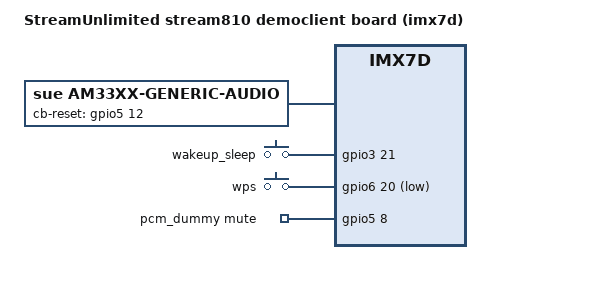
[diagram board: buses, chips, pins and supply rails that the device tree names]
/*
 * This program is free software; you can redistribute it and/or modify
 * it under the terms of the GNU General Public License version 2 as
 * published by the Free Software Foundation.
 */

#include <dt-bindings/input/input.h>

/ {
	pinctrl-names = "default";
	pinctrl-0 = <&pinctrl_audio>;

	model = "StreamUnlimited stream810 democlient board (imx7d)";
	compatible = "sue,stream810-demo", "sue,stream810", "fsl,imx7d";

	audio {
		compatible = "sue,am33xx-generic-audio";
		sue,card-name = "Stream Audio on imx7";

		clocks = <&clks IMX7D_AUDIO_MCLK_ROOT_CLK>,
			 <&clks IMX7D_AUDIO_MCLK_ROOT_CLK>,
			 <&clks IMX7D_PLL_AUDIO_POST_DIV>;
		clock-names = "mclk", "mclk_rx", "pll";

		assigned-clocks = <&clks IMX7D_AUDIO_MCLK_ROOT_SRC>,
				  <&clks IMX7D_AUDIO_MCLK_ROOT_CLK>;
		assigned-clock-parents = <&clks IMX7D_PLL_AUDIO_POST_DIV>;
		assigned-clock-rates = <0>, <24576000>;

		sue,cb-reset-gpio = <&gpio5 12 0>;
		sue,early-mclk;

		links {
			link@0 {
				sue,name = "analog";
				sue,stream-name = "I2S";

				sue,platform = <&sai1>;
				sue,cpu-dai-name = "308a0000.sai";
				sue,codec = <&pcm_dummy>;
				sue,codec-dai-name = "Dummy PCM Codec";
			};
		};
	};

	gpio_keys {
		compatible = "gpio-keys";
		#address-cells = <1>;
		#size-cells = <0>;
		pinctrl-names = "default";
		pinctrl-0 = <&pinctrl_gpio_keys>;

		button@1 {
			label = "wakeup_sleep";
			linux,code = <KEY_SLEEP>;
			gpios = <&gpio3 21 GPIO_ACTIVE_HIGH>;
			gpio-key,wakeup;
		};

		button@2 {
			label = "wps";
			linux,code = <KEY_WPS_BUTTON>;
			gpios = <&gpio6 20 GPIO_ACTIVE_LOW>;
		};
	};

	pcm_dummy: pcm_dummy {
		pinctrl-names = "default";
		pinctrl-0 = <&pinctrl_codec>;

		compatible = "sue,pcm_dummy";
		mute-gpio = <&gpio5 8 0>;
	};
};

/*
 * NOTES for the last number in every line:
 * 	PAD_CTL_PUS_100K_DOWN	(0 << 5)
 * 	PAD_CTL_PUS_5K_UP	(1 << 5)
 * 	PAD_CTL_PUS_47K_UP	(2 << 5)
 * 	PAD_CTL_PUS_100K_UP	(3 << 5)
 * 	PAD_CTL_PUE		(1 << 4)
 * 	PAD_CTL_HYS		(1 << 3)
 * 	PAD_CTL_SRE_SLOW	(1 << 2)
 * 	PAD_CTL_SRE_FAST	(0 << 2)
 * 	PAD_CTL_DSE_X1		(0 << 0) \
 * 	PAD_CTL_DSE_X2		(2 << 0)  |___ NOTE: the numbering here is not a typo!
 * 	PAD_CTL_DSE_X4		(1 << 0)  |
 * 	PAD_CTL_DSE_X6		(3 << 0) /
 * 	NO_PAD_CTL		(1 << 31): indicate this pin does not need config.
 * 	SIO			(1 << 30): Software Input On Field.
 */
&iomuxc {
	imx7d-sue-demo {
		pinctrl_audio: audiogrp {
			fsl,pins = <
				MX7D_PAD_SD2_CLK__GPIO5_IO12	0x00	/* CODEC_NRESET */
			>;
		};

		pinctrl_codec: codecgrp {
			fsl,pins = <
				MX7D_PAD_SD1_DATA3__GPIO5_IO8	0x00	/* AMP mute */
			>;
		};

		pinctrl_gpio_keys: gpiokeysgrp {
			fsl,pins = <
				MX7D_PAD_LCD_DATA16__GPIO3_IO21			0x00		/* BUTTON_SENSE */

				/*
				 * I2S_BCLK_OUT2 (now used for the WPS button since
				 * the GPIO1_IO0 pad from before is now used for the watchdog reset.
				 */
				MX7D_PAD_SAI2_TX_BCLK__GPIO6_IO20		0xF0		/* 100k pull-up */
			>;
		};
	};
};

&iomuxc_lpsr {
	imx7d-sue-demo {
	};
};

